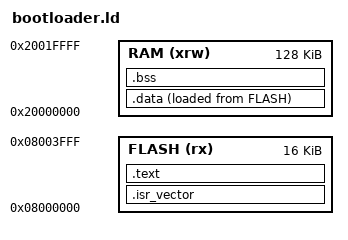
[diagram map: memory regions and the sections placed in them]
ENTRY(Reset_Handler)
_estack = ORIGIN(RAM) + LENGTH(RAM);

MEMORY
{
  RAM   (xrw) : ORIGIN = 0x20000000, LENGTH = 128K
  FLASH (rx)  : ORIGIN = 0x08000000, LENGTH = 16K
}

SECTIONS
{
  .isr_vector : { KEEP(*(.isr_vector)) } >FLASH
  .text :
  {
    *(.text.Reset_Handler) *(.text*) *(.rodata*)
    . = ALIGN(4);
    _etext = .;
  } >FLASH
  _sidata = LOADADDR(.data);
  .data :
  {
    _sdata = .;
    *(.data*)
    . = ALIGN(4);
    _edata = .;
  } >RAM AT>FLASH
  .bss :
  {
    _sbss = .;
    *(.bss*) *(COMMON)
    . = ALIGN(4);
    _ebss = .;
  } >RAM
  /DISCARD/ : { *(.comment*) *(.ARM.attributes*) }
}
